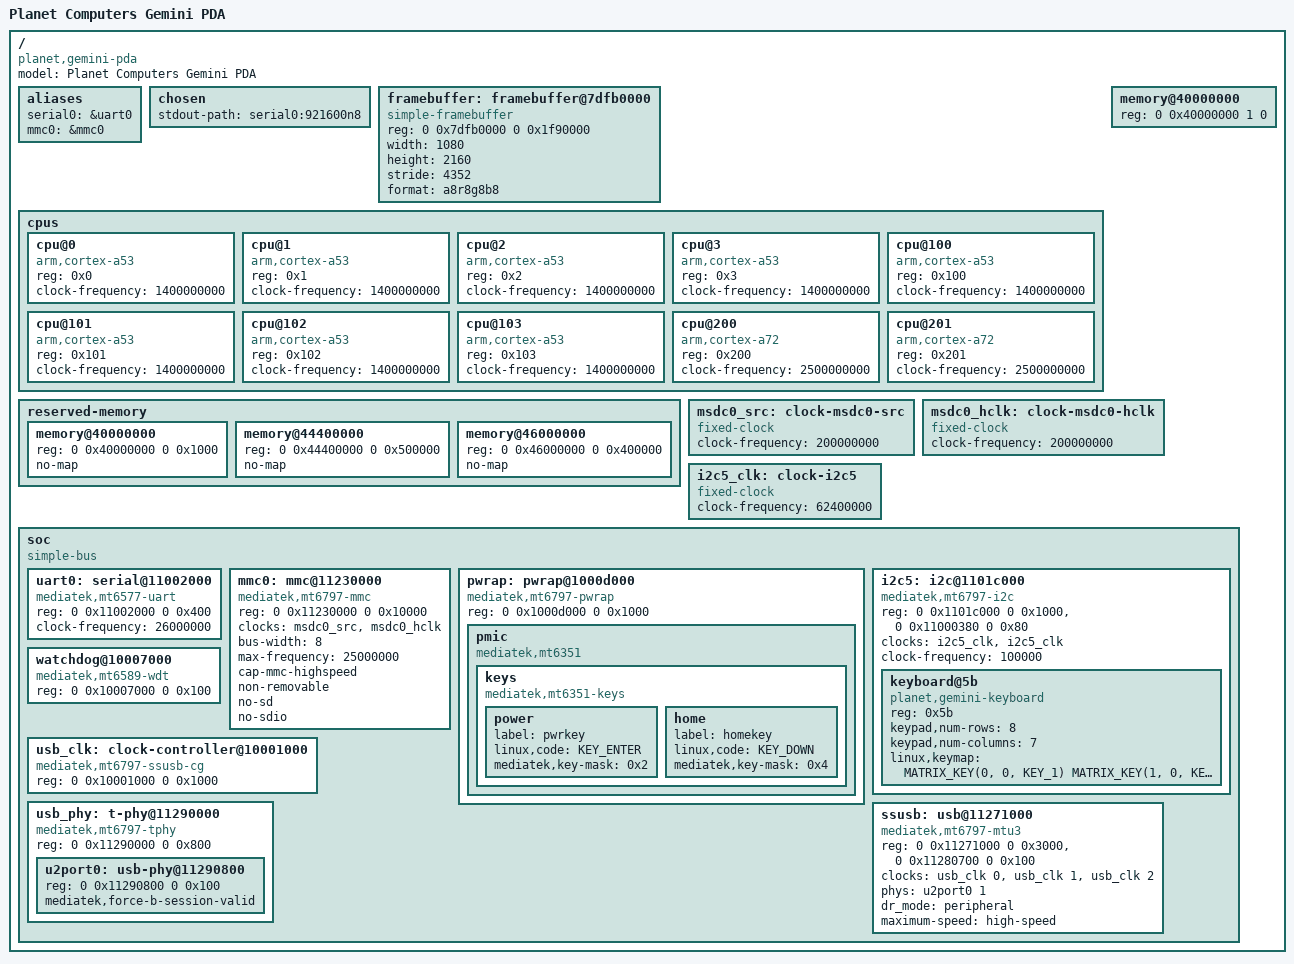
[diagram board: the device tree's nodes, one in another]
// SPDX-License-Identifier: GPL-2.0
/*
 * Device tree for the Planet Computers Gemini PDA (MediaTek MT6797),
 * used as U-Boot's control device tree only.
 *
 * This blob is appended to the boot image. The vendor LK bootloader rewrites
 * /memory, patches every CPU node's clock-frequency and adds its "mblock-*"
 * reserved-memory regions before handing it back to U-Boot in x0. The Linux
 * kernel loads its own, full device tree from the rootfs, so this tree only
 * needs to describe what U-Boot itself drives: the debug UART and the eMMC.
 *
 * It is deliberately self-contained (no SoC .dtsi include): there is no clock,
 * pinctrl or power-domain driver for MT6797 in U-Boot, so clocks are modelled
 * as fixed-clocks and pins/regulators are left as LK configured them.
 */

/dts-v1/;

#include <dt-bindings/input/input.h>

/ {
	model = "Planet Computers Gemini PDA";
	compatible = "planet,gemini-pda", "mediatek,mt6797";
	#address-cells = <2>;
	#size-cells = <2>;

	aliases {
		serial0 = &uart0;
		mmc0 = &mmc0;
	};

	chosen {
		stdout-path = "serial0:921600n8";
	};

	/*
	 * LK leaves its framebuffer live in DRAM and records its base in the
	 * /chosen videolfb atags. These are the hardware-verified parameters
	 * (ixoo's mainline simplefb runs on them); board_init() overwrites the
	 * reg base from the atag at runtime, keeping this as the default.
	 * TODO(hw-verify): base/size/stride confirmed against ixoo's
	 * lk-simplefb.dtso; re-check if the panel or LK revision differs.
	 */
	framebuffer: framebuffer@7dfb0000 {
		compatible = "simple-framebuffer";
		reg = <0 0x7dfb0000 0 0x1f90000>;
		width = <1080>;
		height = <2160>;
		stride = <4352>;
		format = "a8r8g8b8";
		status = "okay";
	};

	/*
	 * LK's target_fdt_cpus() iterates the CPU nodes and bails out on the
	 * first one that is missing clock-frequency, so all ten must carry it.
	 * The values are nominal; LK clamps them to each cluster's maximum.
	 */
	cpus {
		#address-cells = <1>;
		#size-cells = <0>;

		cpu@0 {
			device_type = "cpu";
			compatible = "arm,cortex-a53";
			reg = <0x0>;
			clock-frequency = <1400000000>;
		};

		cpu@1 {
			device_type = "cpu";
			compatible = "arm,cortex-a53";
			reg = <0x1>;
			clock-frequency = <1400000000>;
		};

		cpu@2 {
			device_type = "cpu";
			compatible = "arm,cortex-a53";
			reg = <0x2>;
			clock-frequency = <1400000000>;
		};

		cpu@3 {
			device_type = "cpu";
			compatible = "arm,cortex-a53";
			reg = <0x3>;
			clock-frequency = <1400000000>;
		};

		cpu@100 {
			device_type = "cpu";
			compatible = "arm,cortex-a53";
			reg = <0x100>;
			clock-frequency = <1400000000>;
		};

		cpu@101 {
			device_type = "cpu";
			compatible = "arm,cortex-a53";
			reg = <0x101>;
			clock-frequency = <1400000000>;
		};

		cpu@102 {
			device_type = "cpu";
			compatible = "arm,cortex-a53";
			reg = <0x102>;
			clock-frequency = <1400000000>;
		};

		cpu@103 {
			device_type = "cpu";
			compatible = "arm,cortex-a53";
			reg = <0x103>;
			clock-frequency = <1400000000>;
		};

		cpu@200 {
			device_type = "cpu";
			compatible = "arm,cortex-a72";
			reg = <0x200>;
			clock-frequency = <2500000000>;
		};

		cpu@201 {
			device_type = "cpu";
			compatible = "arm,cortex-a72";
			reg = <0x201>;
			clock-frequency = <2500000000>;
		};
	};

	memory@40000000 {
		device_type = "memory";
		/* Placeholder; LK rewrites /memory with the real banks. */
		reg = <0 0x40000000 1 0>;
	};

	/*
	 * Static pre-LK carve-outs (CCCI/ramoops/SCP/SPM), mirrored from the
	 * Linux DTS so U-Boot's lmb never loads images over them.
	 */
	reserved-memory {
		#address-cells = <2>;
		#size-cells = <2>;
		ranges;

		memory@40000000 {
			reg = <0 0x40000000 0 0x1000>;
			no-map;
		};

		memory@44400000 {
			reg = <0 0x44400000 0 0x500000>;
			no-map;
		};

		memory@46000000 {
			reg = <0 0x46000000 0 0x400000>;
			no-map;
		};
	};

	/*
	 * MSDC0 (eMMC) source clocks. There is no MT6797 clock driver in U-Boot,
	 * so model them as fixed-clocks that LK has already enabled. 200 MHz is
	 * the vendor MSDC50_0 source rate; the controller is capped to 25 MHz
	 * (max-frequency below), which the divider derives from this.
	 * TODO(hw-verify): confirm the MSDC50_0 source rate; any value >= the
	 * 25 MHz cap works, the divider adapts.
	 */
	msdc0_src: clock-msdc0-src {
		compatible = "fixed-clock";
		#clock-cells = <0>;
		clock-frequency = <200000000>;
	};

	msdc0_hclk: clock-msdc0-hclk {
		compatible = "fixed-clock";
		#clock-cells = <0>;
		clock-frequency = <200000000>;
	};

	/*
	 * I2C5 source clock. There is no MT6797 clock driver in U-Boot, so model
	 * it as a fixed-clock LK has already enabled. The mtk_i2c driver divides
	 * this by 4 to get its reference, and the vendor (3.18) MT6797 I2C driver
	 * uses an effective 15.6 MHz source, so 62.4 MHz reproduces that and
	 * yields a ~100 kHz SCL (the driver always clamps to <= clock-frequency).
	 * TODO(hw-verify): confirm the I2C5 source rate; if it is higher the bus
	 * only runs slower, which the AW9523 tolerates.
	 */
	i2c5_clk: clock-i2c5 {
		compatible = "fixed-clock";
		#clock-cells = <0>;
		clock-frequency = <62400000>;
	};

	soc {
		compatible = "simple-bus";
		#address-cells = <2>;
		#size-cells = <2>;
		ranges;

		uart0: serial@11002000 {
			compatible = "mediatek,mt6577-uart";
			reg = <0 0x11002000 0 0x400>;
			/*
			 * No clocks phandle: serial_mtk falls back to this
			 * fixed rate (the 26 MHz UART baud clock LK leaves on).
			 * TODO(hw-verify): confirm the UART0 baud clock is
			 * 26 MHz by checking the banner prints at 921600.
			 */
			clock-frequency = <26000000>;
			status = "okay";
		};

		mmc0: mmc@11230000 {
			compatible = "mediatek,mt6797-mmc";
			reg = <0 0x11230000 0 0x10000>;
			clocks = <&msdc0_src>, <&msdc0_hclk>;
			clock-names = "source", "hclk";
			bus-width = <8>;
			max-frequency = <25000000>;
			cap-mmc-highspeed;
			non-removable;
			no-sd;
			no-sdio;
			status = "okay";
		};

		/*
		 * PMIC wrapper -> MT6351 PMIC. LK has already configured PWRAP,
		 * the PMIC and the pins, so U-Boot only reads the power/home key
		 * state (TOPSTATUS) over WACS2; it does not re-init the wrapper.
		 */
		pwrap: pwrap@1000d000 {
			compatible = "mediatek,mt6797-pwrap";
			reg = <0 0x1000d000 0 0x1000>;

			pmic {
				compatible = "mediatek,mt6351";

				keys {
					compatible = "mediatek,mt6351-keys";

					/*
					 * TODO(hw-verify): Esc(On) is assumed to
					 * be PWRKEY and the silver side button
					 * HOMEKEY. Swap linux,code between the two
					 * nodes if that is reversed on hardware.
					 */
					power {
						label = "pwrkey";
						linux,code = <KEY_ENTER>;
						mediatek,key-mask = <0x2>;
					};

					home {
						label = "homekey";
						linux,code = <KEY_DOWN>;
						mediatek,key-mask = <0x4>;
					};
				};
			};
		};

		/*
		 * I2C5 -> AW9523B GPIO expander (0x5b) driving the built-in
		 * QWERTY keyboard matrix. LK muxes the I2C5 pins (GPIO240/241)
		 * to I2C mode and leaves the expander's reset (GPIO58) as an
		 * input, so U-Boot only needs the bus and the matrix driver.
		 */
		i2c5: i2c@1101c000 {
			compatible = "mediatek,mt6797-i2c", "mediatek,mt6577-i2c";
			reg = <0 0x1101c000 0 0x1000>,
			      <0 0x11000380 0 0x80>;
			clocks = <&i2c5_clk>, <&i2c5_clk>;
			clock-names = "main", "dma";
			clock-frequency = <100000>;
			#address-cells = <1>;
			#size-cells = <0>;
			status = "okay";

			keyboard@5b {
				compatible = "planet,gemini-keyboard";
				reg = <0x5b>;
				keypad,num-rows = <8>;
				keypad,num-columns = <7>;
				/*
				 * 8x7 matrix, mirrored from the Linux Gemini
				 * dts. Fn (KEY_LEFTMETA) has no U-Boot fn layer.
				 */
				linux,keymap = <
					MATRIX_KEY(0, 0, KEY_1)
					MATRIX_KEY(1, 0, KEY_U)
					MATRIX_KEY(2, 0, KEY_S)
					MATRIX_KEY(3, 0, KEY_Z)
					MATRIX_KEY(4, 0, KEY_COMMA)
					MATRIX_KEY(5, 0, KEY_APOSTROPHE)
					MATRIX_KEY(6, 0, KEY_8)
					MATRIX_KEY(7, 0, KEY_J)
					MATRIX_KEY(0, 1, KEY_2)
					MATRIX_KEY(1, 1, KEY_W)
					MATRIX_KEY(2, 1, KEY_D)
					MATRIX_KEY(3, 1, KEY_C)
					MATRIX_KEY(4, 1, KEY_LEFTALT)
					MATRIX_KEY(5, 1, KEY_LEFT)
					MATRIX_KEY(6, 1, KEY_9)
					MATRIX_KEY(7, 1, KEY_K)
					MATRIX_KEY(0, 2, KEY_3)
					MATRIX_KEY(1, 2, KEY_Y)
					MATRIX_KEY(2, 2, KEY_TAB)
					MATRIX_KEY(3, 2, KEY_N)
					MATRIX_KEY(4, 2, KEY_M)
					MATRIX_KEY(5, 2, KEY_DOWN)
					MATRIX_KEY(6, 2, KEY_BACKSPACE)
					MATRIX_KEY(7, 2, KEY_I)
					MATRIX_KEY(0, 3, KEY_4)
					MATRIX_KEY(1, 3, KEY_T)
					MATRIX_KEY(2, 3, KEY_F)
					MATRIX_KEY(3, 3, KEY_X)
					MATRIX_KEY(4, 3, KEY_LEFTMETA)
					MATRIX_KEY(5, 3, KEY_RIGHTSHIFT)
					MATRIX_KEY(6, 3, KEY_P)
					MATRIX_KEY(0, 4, KEY_5)
					MATRIX_KEY(1, 4, KEY_E)
					MATRIX_KEY(2, 4, KEY_G)
					MATRIX_KEY(3, 4, KEY_V)
					MATRIX_KEY(4, 4, KEY_SPACE)
					MATRIX_KEY(5, 4, KEY_UP)
					MATRIX_KEY(6, 4, KEY_O)
					MATRIX_KEY(0, 5, KEY_6)
					MATRIX_KEY(1, 5, KEY_Q)
					MATRIX_KEY(2, 5, KEY_A)
					MATRIX_KEY(3, 5, KEY_B)
					MATRIX_KEY(4, 5, KEY_DOT)
					MATRIX_KEY(5, 5, KEY_RIGHT)
					MATRIX_KEY(6, 5, KEY_ENTER)
					MATRIX_KEY(0, 6, KEY_7)
					MATRIX_KEY(1, 6, KEY_R)
					MATRIX_KEY(2, 6, KEY_H)
					MATRIX_KEY(3, 6, KEY_LEFTSHIFT)
					MATRIX_KEY(4, 6, KEY_LEFTCTRL)
					MATRIX_KEY(5, 6, KEY_L)
					MATRIX_KEY(6, 6, KEY_0)
				>;
			};
		};

		watchdog@10007000 {
			/*
			 * LK leaves the RGU watchdog running (10 s timeout).
			 * TODO(hw-verify): assumes the shipped LK was built
			 * without LK_WDT_DISABLE (it enables the WDT in
			 * mtk_wdt_init() otherwise).
			 */
			compatible = "mediatek,mt6589-wdt";
			reg = <0 0x10007000 0 0x100>;
		};

		/*
		 * infracfg SSUSB gates (sys/ref/bus) consumed by the MTU3
		 * controller. A tiny control-DT-only clock provider, not a full
		 * MT6797 clock driver (see drivers/clk/mediatek/clk-mt6797.c).
		 * Local clock cells: 0 = sys_ck, 1 = ref_ck, 2 = mcu_ck (bus).
		 * Its probe also reparents the topckgen ssusb_top_sys mux.
		 */
		usb_clk: clock-controller@10001000 {
			compatible = "mediatek,mt6797-ssusb-cg";
			reg = <0 0x10001000 0 0x1000>;
			#clock-cells = <1>;
		};

		usb_phy: t-phy@11290000 {
			compatible = "mediatek,mt6797-tphy",
				     "mediatek,generic-tphy-v1";
			reg = <0 0x11290000 0 0x800>;
			#address-cells = <2>;
			#size-cells = <2>;
			ranges;
			status = "okay";

			u2port0: usb-phy@11290800 {
				reg = <0 0x11290800 0 0x100>;
				#phy-cells = <1>;
				/*
				 * VBUS/session is delivered by firmware, not
				 * sensed by the T-PHY, so force a valid B-device
				 * session (mirrors the Linux local quirk). The
				 * "ref" clock is the SSUSB_REF infra gate that
				 * the MTU3 node already enables, so it is omitted
				 * here (optional in the driver).
				 * TODO(hw-verify): confirm it enumerates.
				 */
				mediatek,force-b-session-valid;
				status = "okay";
			};
		};

		/*
		 * MTU3 device controller on the left USB-C port. The
		 * "mediatek,mtu3" fallback matches U-Boot's driver. Peripheral,
		 * high-speed only (no USB3 PHY wired). ippc is at 0x11280700.
		 */
		ssusb: usb@11271000 {
			compatible = "mediatek,mt6797-mtu3", "mediatek,mtu3";
			reg = <0 0x11271000 0 0x3000>,
			      <0 0x11280700 0 0x100>;
			reg-names = "mac", "ippc";
			clocks = <&usb_clk 0>, <&usb_clk 1>, <&usb_clk 2>;
			clock-names = "sys_ck", "ref_ck", "mcu_ck";
			phys = <&u2port0 1>; /* PHY_TYPE_USB2 */
			dr_mode = "peripheral";
			maximum-speed = "high-speed";
			status = "okay";
		};
	};
};
